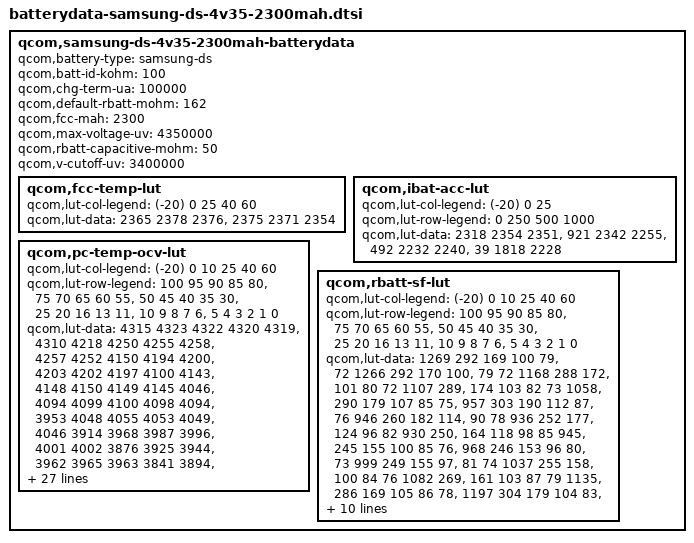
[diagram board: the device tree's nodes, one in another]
/* Copyright (c) 2018, The Linux Foundation. All rights reserved.
*  Copyright (c) 2018, Ketut P. Kumajaya.
*  Copyright (c) 2020, the_shahnawaz_sheikh (sheikhshahnawaz41299).
*
* This program is free software; you can redistribute it and/or modify
* it under the terms of the GNU General Public License version 2 and
* only version 2 as published by the Free Software Foundation.
*
* This program is distributed in the hope that it will be useful,
* but WITHOUT ANY WARRANTY; without even the implied warranty of
* MERCHANTABILITY or FITNESS FOR A PARTICULAR PURPOSE.  See the
* GNU General Public License for more details.
*/

qcom,samsung-ds-4v35-2300mah-batterydata {
	qcom,battery-type = "samsung-ds";
	qcom,batt-id-kohm = <100>;
	qcom,chg-term-ua = <100000>;
	qcom,default-rbatt-mohm = <162>;
	qcom,fcc-mah = <2300>;
	qcom,max-voltage-uv = <4350000>;
	qcom,rbatt-capacitive-mohm = <50>;
	qcom,v-cutoff-uv = <3400000>;

	qcom,fcc-temp-lut {
		qcom,lut-col-legend = <(-20) 0 25 40 60>;
		qcom,lut-data = <2365 2378 2376>, 
		                 <2375 2371 2354>;
	};

	qcom,ibat-acc-lut {
		qcom,lut-col-legend = <(-20) 0 25>;
		qcom,lut-row-legend = <0 250 500 1000>;
		qcom,lut-data = <2318 2354 2351>,
		                 <921 2342 2255>,
						 <492 2232 2240>,
						 <39 1818 2228>;
	};

	qcom,pc-temp-ocv-lut {
		qcom,lut-col-legend = <(-20) 0 10 25 40 60>;
		qcom,lut-row-legend = <100 95 90 85 80>,
		                       <75 70 65 60 55>,
							   <50 45 40 35 30>,
							   <25 20 16 13 11>,
							   <10 9 8 7 6>,
							   <5 4 3 2 1 0>;
		qcom,lut-data = <4315 4323 4322 4320 4319>,
		                 <4310 4218 4250 4255 4258>,
						 <4257 4252 4150 4194 4200>,
						 <4203 4202 4197 4100 4143>,
						 <4148 4150 4149 4145 4046>,
						 <4094 4099 4100 4098 4094>,
						 <3953 4048 4055 4053 4049>,
						 <4046 3914 3968 3987 3996>,
						 <4001 4002 3876 3925 3944>,
						 <3962 3965 3963 3841 3894>,
						 <3905 3920 3924 3923 3819>,
						 <3861 3868 3874 3876 3875>,
						 <3801 3834 3839 3842 3843>,
						 <3843 3786 3811 3816 3819>,
						 <3820 3820 3772 3792 3798>,
						 <3801 3802 3801 3758 3780>,
						 <3783 3785 3785 3785 3743>,
						 <3768 3772 3772 3769 3765>,
						 <3728 3754 3761 3758 3751>,
						 <3739 3713 3734 3743 3740>,
						 <3732 3718 3697 3716 3720>,
						 <3717 3709 3696 3683 3706>,
						 <3701 3694 3686 3673 3670>,
						 <3699 3695 3689 3681 3670>,
						 <3662 3696 3693 3688 3680>,
						 <3669 3653 3693 3691 3686>,
						 <3680 3668 3643 3691 3690>,
						 <3685 3678 3667 3629 3685>,
						 <3687 3683 3676 3664 3612>,
						 <3677 3681 3678 3670 3655>,
						 <3590 3660 3664 3661 3648>,
						 <3629 3558 3625 3626 3615>,
						 <3604 3584 3514 3571 3568>,
						 <3554 3545 3524 3445 3493>,
						 <3488 3472 3466 3441 3323>,
						 <3367 3362 3341 3351 3311>,
						 <3000 3000 3000 3000 3060>,
						 <3000>;
	};

	qcom,rbatt-sf-lut {
		qcom,lut-col-legend = <(-20) 0 10 25 40 60>;
		qcom,lut-row-legend = <100 95 90 85 80>,
		                       <75 70 65 60 55>,
							   <50 45 40 35 30>,
							   <25 20 16 13 11>,
							   <10 9 8 7 6>,
							   <5 4 3 2 1 0>;
		qcom,lut-data = <1269 292 169 100 79>,
		                 <72 1266 292 170 100>,
						 <79 72 1168 288 172>,
						 <101 80 72 1107 289>,
						 <174 103 82 73 1058>,
						 <290 179 107 85 75>,
						 <957 303 190 112 87>,
						 <76 946 260 182 114>,
						 <90 78 936 252 177>,
						 <124 96 82 930 250>,
						 <164 118 98 85 945>,
						 <245 155 100 85 76>,
						 <968 246 153 96 80>,
						 <73 999 249 155 97>,
						 <81 74 1037 255 158>,
						 <100 84 76 1082 269>,
						 <161 103 87 79 1135>,
						 <286 169 105 86 78>,
						 <1197 304 179 104 83>,
						 <74 1269 319 186 103>,
						 <83 74 1322 332 190>,
						 <104 83 75 1301 341>,
						 <186 100 81 72 1305>,
						 <356 191 101 81 73>, 
						 <1336 367 198 103 83>,
						 <75 1366 382 204 106>,
						 <85 76 1400 396 215>, 
						 <110 87 77 1434 416>,
						 <225 113 89 80 1468>,
						 <436 237 118 91 80>,
						 <1518 452 245 116 87>, 
						 <76 1673 462 247 113>, 
						 <86 76 1962 484 258>,
						 <117 88 77 2416 525>, 
						 <281 124 92 82 3724>,
						 <598 331 160 102 95>,
						 <100412 102416 99755 94299 281 65192>;
	};
};

